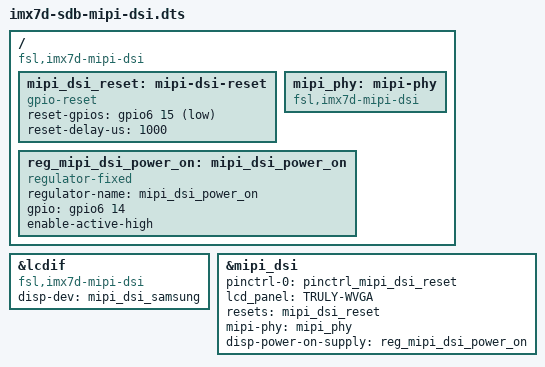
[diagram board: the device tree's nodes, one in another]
/*
 * Copyright (C) 2016 Freescale Semiconductor, Inc.
 *
 * This program is free software; you can redistribute it and/or modify
 * it under the terms of the GNU General Public License version 2 as
 * published by the Free Software Foundation.
 */

#include "imx7d-sdb.dts"

/ {
    compatible = "fsl,imx7d-mipi-dsi";
    
    mipi_dsi_reset: mipi-dsi-reset {
        compatible = "gpio-reset";
        reset-gpios = <&gpio6 15 GPIO_ACTIVE_LOW>;
        reset-delay-us = <1000>;
        #reset-cells = <0>;
    };
   
    
    mipi_phy: mipi-phy {
        compatible = "fsl,imx7d-mipi-dsi";
         /*phy_data_lanes = <2>;
        max_phy_clock = <80000000>;
        phy_mode = "rgb";*/
    }; 
       
   reg_mipi_dsi_power_on: mipi_dsi_power_on {
        compatible = "regulator-fixed";
        regulator-name = "mipi_dsi_power_on";
        gpio = <&gpio6 14 0>;
        enable-active-high;
    };
    
/*    mxcfb1:fb@0{
        compatible = "fsl,mxc_sdc_fb";
        disp_dev = "mipi_dsi_samsung";
        interface_pix_fmt = "RGB565";
        mode_str = "TRULY-WVGA";
        default_bpp = <16>;
        int_clk = <0>;
        lete_init = <0>;
        status = "okay";
    }; */
}; 
     
    &lcdif {
        disp-dev = "mipi_dsi_samsung";
        compatible = "fsl,imx7d-mipi-dsi";
    };
    
    &mipi_dsi {
    pinctrl-names = "default";
    pinctrl-0 = <&pinctrl_mipi_dsi_reset>;
    lcd_panel = "TRULY-WVGA";
    resets = <&mipi_dsi_reset>;
    mipi-phy = <&mipi_phy>;
    disp-power-on-supply = <&reg_mipi_dsi_power_on>;
    status = "okay";
    };
